# H5 register map
Vendor: Allwinner; Series: H5; File version: 0.1
CPU: 0, little endian, MPU, no FPU, 0 interrupt priority bits
Registers are 32-bit, read-write, reset 0x0 unless marked. A register's access mark holds for its fields unless they carry their own. Offsets are from the block's base; [hi:lo] are bit positions.

## R_TWI
Base 0x01F02400
Same registers: TWI0 0x01C2AC00, TWI1 0x01C2B000, TWI2 0x01C2B400
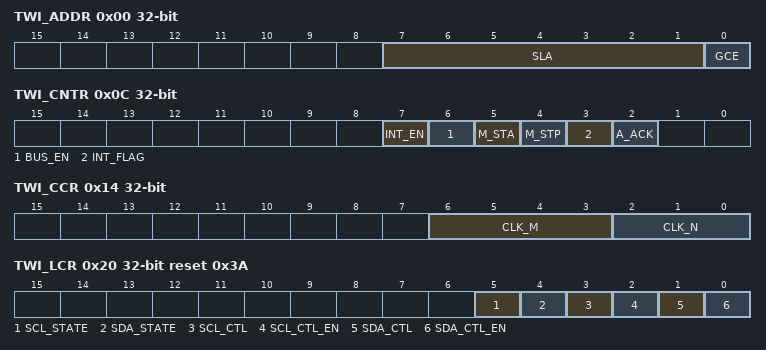
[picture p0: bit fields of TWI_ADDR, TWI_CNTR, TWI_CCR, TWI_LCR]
0x00 TWI_ADDR — TWI Slave Address Register
  [7:1] SLA — Slave address 7-bit addressing SLA6, SLA5, SLA4, SLA3, SLA2, SLA1, SLA0 10-bit addressing 1, 1, 1, 1, 0, SLAX[9:8]
  [0] GCE — General call address enable 0: Disable 1: Enable
    0=Disable; 1=Enable
0x04 TWI_XADDR — TWI Extended Slave Address Register
  [7:0] SLAX — Extend Slave Address SLAX[7:0]
0x08 TWI_DATA — TWI Data Byte Register
  [7:0] TWI_DATA — Data byte for transmitting or received
0x0C TWI_CNTR — TWI Control Register
  [7] INT_EN — Interrupt Enable 0: The interrupt line always low 1: The interrupt line will go high when INT_FLAG is set.
    0=interrupt_line_always_low (The interrupt line always low); 1=interrupt_line_will_go (The interrupt line will go high when INT_FLAG is set.)
  [6] BUS_EN — TWI Bus Enable 0: The TWI bus inputs ISDA/ISCL are ignored and the TWI controller will not respond to any address on the bus 1: The TWI will respond to call to its slave address - and to the general call address if the GCE bit in the TWI_ADDR register is set. Note: I aste ope atio ode, this it should e set to .
    0=TWI_bus (The TWI bus inputs ISDA/ISCL are ignored and the TWI controller will not respond to any address on the bus); 1=TWI_will_respond (The TWI will respond to call to its slave address - and to the general call address if the GCE bit in the TWI_ADDR register is set. Note: I aste ope atio ode, this it should e set to .)
  [5] M_STA — Master Mode Start When M_STA is set to , the TWI o t olle e te s aste ode a d ill transmit a START condition on the bus when the bus is free. If M_STA is se t to he the TWI o t olle is al ead i aste ode a d one or more bytes have been transmitted, then a repeated START condition will be sent. If M_STA is set to he the TWI is a cessed in slave mode, the TWI will complete the data transfer in slave mode then enter master mode when the bus has been released. M_STA is cleared automatically after a START condition sent. W iti g a to this it has o effe t.
  [4] M_STP — Master Mode Stop If M_STP is set to i aste ode, a STOP o ditio is t a s itted o the TWI bus. If M_STP is set to i sla e ode, the TWI ill eha e as if a STOP condition has been received, but no STOP condition will be transmitted on the TWI bus. If both M_STA and M_STP are set, the TWI will first transmit the STOP condition (if in master mode) then transmit the START condition. M_STP is cleared automatically. W iti g a to this it has o effe t.
  [3] INT_FLAG — Interrupt Flag INT_FLAG is auto ati all set to he a of out of the possi le 29) states is e te ed see TWI_STAT elo . INT_FLAG can not be set when TWI code state is F8h. If the INT_EN bit is set, the interrupt line goes high when INT_FLAG is set to . If the TWI is operating in slave mode, data transfer is suspended when INT_FLAG is set and the low period of the TWI bus clock line (SCL) is st et hed u til is itte to INT_FLAG . The TWI clock line is then released and the interrupt line goes low.
  [2] A_ACK — Assert Acknowledge When A_ACK is set to , a A k o ledge lo le el o SDA ill e se t during the acknowledge clock pulse on the TWI bus if: (1). Either the whole of a matching 7-bit slave address or the first or the second byte of a matching 10-bit slave address has been received. (2). The general call address has been received and the GCE bit in the TWI_ADDR egiste is set to . (3). A data byte has been received in master or slave mode. When A_ACK is , a Not A k o ledge high le el o SDA ill e se t he a data byte is received in master or slave mode. If A_ACK is lea ed to i sla e t a nsmitter mode, the byte in the DATA egiste is assu ed to e the last te . Afte this te has ee t a s itted, the TWI will enter state C8h then return to the idle state (status code F8h) when INT_FLAG is cleared. The TWI will not respond as a slave unless A_ACK is set.
0x10 TWI_STAT reset 0xF8 — TWI Status Register
  [7:0] STA ro — Status Information Byte Code Status 0x00: Bus error 0x08: START condition transmitted 0x10: Repeated START condition transmitted 0x18: Address + Write bit transmitted, ACK received 0x20: Address + Write bit transmitted, ACK not received 0x28: Data byte transmitted in master mode, ACK received 0x30: Data byte transmitted in master mode, ACK not received 0x38: Arbitration lost in address or data byte 0x40: Address + Read bit transmitted, ACK received 0x48: Address + Read bit transmitted, ACK not received 0x50: Data byte received in master mode, ACK transmitted 0x58: Data byte received in master mode, ACK not transmitted 0x60: Slave address + Write bit received, ACK transmitted 0x68: Arbitration lost in address as master, slave address + Write bit received, ACK transmitted 0x70: General Call address received, ACK transmitted 0x78: Arbitration lost in address as master, General Call address received, ACK transmitted 0x80: Data byte received after slave address received, ACK transmitted 0x88: Data byte received after slave address received, ACK not transmitted 0x90: Data byte received after General Call received, ACK transmitted 0x98: Data byte received after General Call received, ACK not transmitted 0xA0: STOP or repeated START condition received in slave mode 0xA8: Slave address + Read bit received, ACK transmitted 0xB0: Arbitration lost in address as master, slave address + Read bit received, ACK transmitted 0xB8: Data byte transmitted in slave mode, ACK received 0xC0: Data byte transmitted in slave mode, ACK not received 0xC8: Last byte transmitted in slave mode, ACK received 0xD0: Second Address byte + Write bit transmitted, ACK received 0xD8: Second Address byte + Write bit transmitted, ACK not received 0xF8: No relevant status information, INT_FLAG=0 Others: Reserved
0x14 TWI_CCR — TWI Clock Control Register
  [6:3] CLK_M
  [2:0] CLK_N — The TWI bus is sampled by the TWI at the frequency defined by F0: Fsamp = F0 = Fin / 2^CLK_N The TWI OSCL output frequency, in master mode, is F1 / 10: F1 = F0 / (CLK_M + 1) Foscl = F1 / 10 = Fin / (2^CLK_N * (CLK_M + 1)*10) For Example Fin = 48MHz (APB clock input) For 400KHz full speed 2Wire, CLK_N = 2, CLK_M=2 F0 = 48M/2^2=12MHz, F1= F0/(10*(2+1)) = 0.4MHz For 100KHz standard speed 2Wire, CLK_N=2, CLK_M=11 F0=48M/2^2=12MHz, F1=F0/(10*(11+1)) = 0.1MHz
0x18 TWI_SRST — TWI Software Reset Register
  [0] SOFT_RST — Soft Reset W ite to this it to eset the TWI a d lea to he o pleti g Soft Reset operation.
0x1C TWI_EFR — TWI Enhance Feature Register
  [1:0] DBN — Data Byte number follow Read Command Control 00: No Data Byte to be written after read command 01: Only 1 byte data to be written after read command 10: 2 bytes data can be written after read command 11: 3 bytes data can be written after read command
    0=No Data Byte to be written after read command; 1=Only 1 byte data to be written after read command; 2=2 bytes data can be written after read command; 3=3 bytes data can be written after read command
0x20 TWI_LCR reset 0x3A — TWI Line Control Register
  [5] SCL_STATE ro — Current state of TWI_SCL 0: Low 1: High
    0=Low; 1=High
  [4] SDA_STATE ro — Current state of TWI_SDA 0: Low 1: High
    0=Low; 1=High
  [3] SCL_CTL — TWI_SCL line state control bit When line control mode is enabled ( SCL_CTL_EN is set), this bit decide the output level of TWI_SCL. 0: Output low level 1: Output high level
    0=Output_low_level; 1=Output_high_level
  [2] SCL_CTL_EN — TWI_SCL line state control enable When this bit is set, the state of TWI_SCL is controlled by the value of SCL_CTL . 0: Disable TWI_SCL line control mode 1: Enable TWI_SCL line control mode
    0=Disable TWI_SCL line control mode; 1=Enable TWI_SCL line control mode
  [1] SDA_CTL — TWI_SDA line state control bit When line control mode is enabled ( SDA_CTL_EN is set), this bit decides the output level of TWI_SDA. 0: Output low level 1: Output high level
    0=Output_low_level; 1=Output_high_level
  [0] SDA_CTL_EN — TWI_SDA line state control enable When this bit is set, the state of TWI_SDA is controlled by the value of SDA_CTL . 0: Disable TWI_SDA line control mode 1: Enable TWI_SDA line control mode
    0=Disable TWI_SDA line control mode; 1=Enable TWI_SDA line control mode
